# STM32H757_CM4 register map
File version: 2.3
CPU: CM4 r0p1, little endian, MPU, FPU, 4 interrupt priority bits
Registers are 32-bit, read-write, reset 0x0 unless marked. A register's access mark holds for its fields unless they carry their own. Offsets are from the block's base; [hi:lo] are bit positions; {n}, {i} and the like mark numbered series.

## PWR
Base 0x58024800
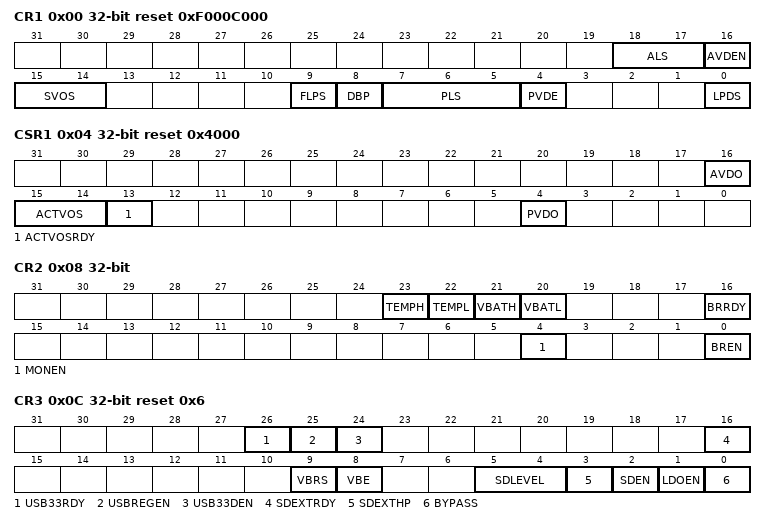
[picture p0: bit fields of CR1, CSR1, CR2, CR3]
0x00 CR1 reset 0xF000C000 — PWR control register 1
  [18:17] ALS — Analog voltage detector level selection These bits select the voltage threshold detected by the AVD.
  [16] AVDEN — Peripheral voltage monitor on VDDA enable
  [15:14] SVOS — System Stop mode voltage scaling selection These bits control the VCORE voltage level in system Stop mode, to obtain the best trade-off between power consumption and performance.
  [9] FLPS — Flash low-power mode in DStop mode This bit allows to obtain the best trade-off between low-power consumption and restart time when exiting from DStop mode. When it is set, the Flash memory enters low-power mode when D1 domain is in DStop mode.
  [8] DBP — Disable backup domain write protection In reset state, the RCC_BDCR register, the RTC registers (including the backup registers), BREN and MOEN bits in PWR_CR2 register, are protected against parasitic write access. This bit must be set to enable write access to these registers.
  [7:5] PLS — Programmable voltage detector level selection These bits select the voltage threshold detected by the PVD. Note: Refer to Section Electrical characteristics of the product datasheet for more details.
  [4] PVDE — Programmable voltage detector enable
  [0] LPDS — Low-power Deepsleep with SVOS3 (SVOS4 and SVOS5 always use low-power, regardless of the setting of this bit)
0x04 CSR1 ro reset 0x4000 — PWR control status register 1
  [16] AVDO — Analog voltage detector output on VDDA This bit is set and cleared by hardware. It is valid only if AVD on VDDA is enabled by the AVDEN bit. Note: Since the AVD is disabled in Standby mode, this bit is equal to 0 after Standby or reset until the AVDEN bit is set.
  [15:14] ACTVOS — VOS currently applied for VCORE voltage scaling selection. These bits reflect the last VOS value applied to the PMU.
  [13] ACTVOSRDY — Voltage levels ready bit for currently used VOS and SDLEVEL This bit is set to 1 by hardware when the voltage regulator and the SD converter are both disabled and Bypass mode is selected in PWR control register 3 (PWR_CR3).
  [4] PVDO — Programmable voltage detect output This bit is set and cleared by hardware. It is valid only if the PVD has been enabled by the PVDE bit. Note: since the PVD is disabled in Standby mode, this bit is equal to 0 after Standby or reset until the PVDE bit is set.
0x08 CR2 access per field — This register is not reset by wakeup from Standby mode, RESET signal and VDD POR. It is only reset by VSW POR and VSWRST reset. This register shall not be accessed when VSWRST bit in RCC_BDCR register resets the VSW domain.After reset, PWR_CR2 register is write-protected. Prior to modifying its content, the DBP bit in PWR_CR1 register must be set to disable the write protection.
  [23] TEMPH ro — Temperature level monitoring versus high threshold
  [22] TEMPL ro — Temperature level monitoring versus low threshold
  [21] VBATH ro — VBAT level monitoring versus high threshold
  [20] VBATL ro — VBAT level monitoring versus low threshold
  [16] BRRDY ro — Backup regulator ready This bit is set by hardware to indicate that the Backup regulator is ready.
  [4] MONEN rw — VBAT and temperature monitoring enable When set, the VBAT supply and temperature monitoring is enabled.
  [0] BREN rw — Backup regulator enable When set, the Backup regulator (used to maintain the backup RAM content in Standby and VBAT modes) is enabled. If BREN is reset, the backup regulator is switched off. The backup RAM can still be used in Run and Stop modes. However, its content will be lost in Standby and VBAT modes. If BREN is set, the application must wait till the Backup Regulator Ready flag (BRRDY) is set to indicate that the data written into the SRAM will be maintained in Standby and VBAT modes.
0x0C CR3 access not given reset 0x6 — Reset only by POR only, not reset by wakeup from Standby mode and RESET pad. The lower byte of this register is written once after POR and shall be written before changing VOS level or ck_sys clock frequency. No limitation applies to the upper bytes.Programming data corresponding to an invalid combination of SDLEVEL, SDEXTHP, SDEN, LDOEN and BYPASS bits (see Table9) will be ignored: data will not be written, the written-once mechanism will lock the register and any further write access will be ignored. The default supply configuration will be kept and the ACTVOSRDY bit in PWR control status register 1 (PWR_CSR1) will go on indicating invalid voltage levels. The system shall be power cycled before writing a new value.
  [26] USB33RDY ro — USB supply ready.
  [25] USBREGEN rw — USB regulator enable.
  [24] USB33DEN wo — VDD33USB voltage level detector enable.
  [16] SDEXTRDY — SMPS step-down converter external supply ready
  [9] VBRS rw — VBAT charging resistor selection
  [8] VBE rw — VBAT charging enable
  [5:4] SDLEVEL — SMPS step-down converter voltage output level selection
  [3] SDEXTHP — SMPS step-down converter forced ON and in High Power MR mode
  [2] SDEN rw — SD converter Enable
  [1] LDOEN rw — Low drop-out regulator enable
  [0] BYPASS rw — Power management unit bypass
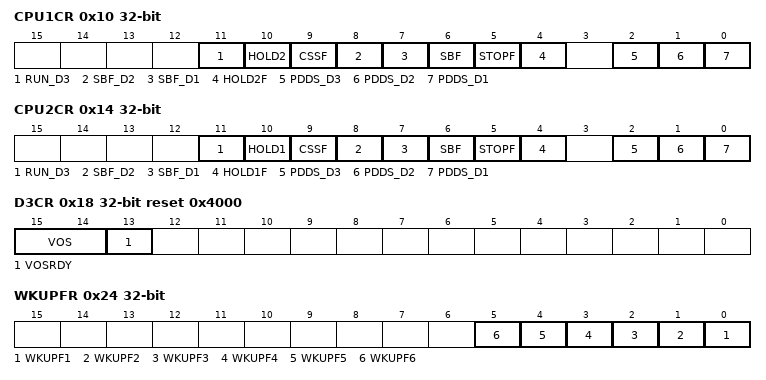
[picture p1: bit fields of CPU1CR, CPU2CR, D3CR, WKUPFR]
0x10 CPU1CR access not given — This register allows controlling CPU1 power.
  [11] RUN_D3 rw — Keep system D3 domain in Run mode regardless of the CPU sub-systems modes
  [10] HOLD2 — Hold the CPU2 and allocated peripherals when exiting from Stop mode.
  [9] CSSF rw — Clear D1 domain CPU1 Standby, Stop and HOLD flags (always read as 0) This bit is cleared to 0 by hardware.
  [8] SBF_D2 ro — D2 domain DStandby flag This bit is set by hardware and cleared by any system reset or by setting the CPU1 CSSF bit. Once set, this bit can be cleared only when the D2 domain is no longer in DStandby mode.
  [7] SBF_D1 ro — D1 domain DStandby flag This bit is set by hardware and cleared by any system reset or by setting the CPU1 CSSF bit. Once set, this bit can be cleared only when the D1 domain is no longer in DStandby mode.
  [6] SBF ro — System Standby flag This bit is set by hardware and cleared only by a POR (Power-on Reset) or by setting the CPU1 CSSF bit
  [5] STOPF ro — STOP flag This bit is set by hardware and cleared only by any reset or by setting the CPU1 CSSF bit.
  [4] HOLD2F — CPU2 in hold wakeup flag. This flag also generates a CPU1 interrupt. CPU1 has been woken up from a CPU2 wakeup source with CPU2 on hold. This flag is set by hardware and cleared only by a system reset or by setting the CPU1 CSSF bit.
  [2] PDDS_D3 rw — System D3 domain Power Down Deepsleep. This bit allows CPU1 to define the Deepsleep mode for System D3 domain.
  [1] PDDS_D2 rw — D2 domain Power Down Deepsleep. This bit allows CPU1 to define the Deepsleep mode for D2 domain.
  [0] PDDS_D1 rw — D1 domain Power Down Deepsleep selection. This bit allows CPU1 to define the Deepsleep mode for D1 domain.
0x14 CPU2CR access not given — This register allows controlling CPU2 power
  [11] RUN_D3 — Keep D3 domain in Run mode regardless of the other CPU subsystems modes.
  [10] HOLD1 — Hold the CPU1 and allocated peripherals when exiting from Stop mode.
  [9] CSSF — Clear D2 domain CPU2 Standby, Stop and HOLD flags (always read as 0)
  [8] SBF_D2 — D2 domain DStandby flag. This bit is set by hardware and cleared by any Reset or by setting the CPU2 CSSF bit. Once set, this bit can be cleared only when the D2 domain is no longer in DStandby mode.
  [7] SBF_D1 — D1 domain DStandby flag. This bit is set by hardware and cleared only by a POR (Power-on Reset) or by setting the CPU2 CSSF bit
  [6] SBF — System Standby flag. This bit is set by hardware and cleared only by a POR (Power-on Reset) or by setting the CPU2 CSSF bit
  [5] STOPF — Stop Flag. This bit is set by hardware and cleared only by any reset or by setting the CPU2 CSSF bit.
  [4] HOLD1F — CPU1 in hold wakeup flag. This flag also generates a CPU2 interrupt. CPU2 has been woken up from a CPU1 wakeup source with CPU1 on hold. This flag is set by hardware and cleared only by a system reset or by setting the CPU2 CSSF bit.
  [2] PDDS_D3 — D3 domain Power Down Deepsleep selection. This bit allows CPU2 to define the Deepsleep mode for D3 domain
  [1] PDDS_D2 — D2 domain Power Down Deepsleep selection. This bit allows CPU2 to define the Deepsleep mode for D2 domain
  [0] PDDS_D1 — D1 domain Power Down Deepsleep selection. This bit allows CPU2 to define the Deepsleep mode for D1 domain
0x18 D3CR access per field reset 0x4000 — This register allows controlling D3 domain power.Following reset VOSRDY will be read 1 by software
  [15:14] VOS rw — Voltage scaling selection according to performance These bits control the VCORE voltage level and allow to obtains the best trade-off between power consumption and performance: When increasing the performance, the voltage scaling shall be changed before increasing the system frequency. When decreasing performance, the system frequency shall first be decreased before changing the voltage scaling.
  [13] VOSRDY ro — VOS Ready bit for VCORE voltage scaling output selection. This bit is set to 1 by hardware when Bypass mode is selected in PWR control register 3 (PWR_CR3).
0x20 WKUPCR — reset only by system reset, not reset by wakeup from Standby mode5 wait states are required when writing this register (when clearing a WKUPF bit in PWR_WKUPFR, the AHB write access will complete after the WKUPF has been cleared).
  [5:0] WKUPC — Clear Wakeup pin flag for WKUP. These bits are always read as 0.
0x24 WKUPFR — reset only by system reset, not reset by wakeup from Standby mode
  [n-1] WKUPF{n} (n=1..6) — Wakeup pin WKUPF flag. This bit is set by hardware and cleared only by a Reset pin or by setting the WKUPCn+1 bit in the PWR wakeup clear register (PWR_WKUPCR).
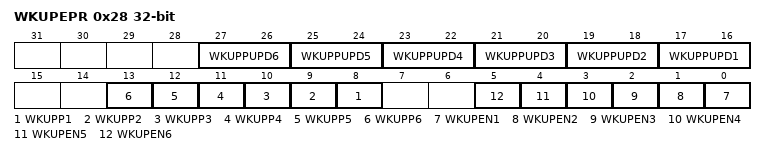
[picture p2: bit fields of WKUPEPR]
0x28 WKUPEPR — Reset only by system reset, not reset by wakeup from Standby mode
  [27:26] WKUPPUPD6 — Wakeup pin pull configuration for WKUP(truncate(n/2)-7) These bits define the I/O pad pull configuration used when WKUPEN(truncate(n/2)-7) = 1. The associated GPIO port pull configuration shall be set to the same value or to 00. The Wakeup pin pull configuration is kept in Standby mode.
  [2n+15:2n+14] WKUPPUPD{n} (n=1..5) — Wakeup pin pull configuration
  [n+7] WKUPP{n} (n=1..6) — Wakeup pin polarity bit for WKUPn-7 These bits define the polarity used for event detection on WKUPn-7 external wakeup pin.
  [n-1] WKUPEN{n} (n=1..6) — Enable Wakeup Pin WKUPn+1 Each bit is set and cleared by software. Note: An additional wakeup event is detected if WKUPn+1 pin is enabled (by setting the WKUPENn+1 bit) when WKUPn+1 pin level is already high when WKUPPn+1 selects rising edge, or low when WKUPPn+1 selects falling edge.
